AUTOSAR XML (schema 4-3-0)
package /Impl_SWC_HALIN_CDD_ARPkg
  swc implementation Impl_SWC_HALIN_CDD_type: programming-language=C, sw-version=1.0.0, vendor-id=0, behavior=SWC_HALIN_CDD_type_IB
    code-descriptors:
      code SRC: artifact-descriptors=autosar-engineering-object={short-label=EngObject, category=SWSRC}
    resource consumption ResourceConsumption
      memory section Mem_SWC_HALIN_CDD_CAL: size=0, sw-addrmethod=CAL, symbol=CAL
      memory section Mem_SWC_HALIN_CDD_CODE: size=0, sw-addrmethod=CODE, symbol=CODE
package /Impl_Type_HALIN_CDD_ARPkg
  13 x impl type:
    BHAL_APM_outputs: category=STRUCTURE
      58 x element, all with category=TYPE_REFERENCE:
        VHAL_PASDRMR_cm: implementation-data-type=uint8
        VHAL_PASDRML_cm: implementation-data-type=uint8
        VHAL_PASDRCR_cm: implementation-data-type=uint8
        VHAL_PASDRCL_cm: implementation-data-type=uint8
        VHAL_PASDFMR_cm: implementation-data-type=uint8
        VHAL_PASDFML_cm: implementation-data-type=uint8
        VHAL_PASDFCR_cm: implementation-data-type=uint8
        VHAL_PASDFCL_cm: implementation-data-type=uint8
        VHAL_APSDRLR_cm: implementation-data-type=uint16
        VHAL_APSDRLL_cm: implementation-data-type=uint16
        VHAL_APSDFLR_cm: implementation-data-type=uint16
        VHAL_APSDFLL_cm: implementation-data-type=uint16
        VHAL_PASAFCL_enum: implementation-data-type=uint8
        VHAL_PASARMR_enum: implementation-data-type=uint8
        VHAL_PASARML_enum: implementation-data-type=uint8
        VHAL_PASARCR_enum: implementation-data-type=uint8
        VHAL_PASARCL_enum: implementation-data-type=uint8
        VHAL_PASAFMR_enum: implementation-data-type=uint8
        VHAL_PASAFML_enum: implementation-data-type=uint8
        VHAL_PASAFCR_enum: implementation-data-type=uint8
        VHAL_USSStaRMR_flg: implementation-data-type=boolean
        VHAL_USSStaRML_flg: implementation-data-type=boolean
        VHAL_USSStaRLR_flg: implementation-data-type=boolean
        VHAL_USSStaRLL_flg: implementation-data-type=boolean
        VHAL_USSStaRCR_flg: implementation-data-type=boolean
        VHAL_USSStaRCL_flg: implementation-data-type=boolean
        VHAL_USSStaFMR_flg: implementation-data-type=boolean
        VHAL_USSStaFML_flg: implementation-data-type=boolean
        VHAL_USSStaFLR_flg: implementation-data-type=boolean
        VHAL_USSStaFLL_flg: implementation-data-type=boolean
        VHAL_USSStaFCR_flg: implementation-data-type=boolean
        VHAL_USSStaFCL_flg: implementation-data-type=boolean
        VHAL_Chime_enum: implementation-data-type=uint8
        VHAL_SNSRLayout_enum: implementation-data-type=uint8
        VHAL_StaFSya_flg: implementation-data-type=boolean
        VHAL_ModOperation_enum: implementation-data-type=uint8
        VHAL_APSProgressPCT_pct: implementation-data-type=float32
        VHAL_APSRQDisplay_enum: implementation-data-type=uint8
        VHAL_APSSWVer_enum: implementation-data-type=uint8
        VHAL_APSHWVer_enum: implementation-data-type=uint8
        VHAL_APSExitCondition_enum: implementation-data-type=uint8
        VHAL_APSAngleTarget_Deg: implementation-data-type=float32
        VHAL_APSStaSystem_enum: implementation-data-type=uint8
        VHAL_APSVRqEPASCtrl_flg: implementation-data-type=boolean
        VHAL_APSRqEPASCtrl_flg: implementation-data-type=boolean
        VHAL_APSReq_enum: implementation-data-type=uint8
        VHAL_APSDecReq_mps2: implementation-data-type=float32
        VHAL_APSDecReqA_flg: implementation-data-type=boolean
        VHAL_APSShiftPosnReq_enum: implementation-data-type=uint8
        VHAL_APSSpeedCMD_kph: implementation-data-type=float32
        VHAL_APSVMCReqA_flg: implementation-data-type=boolean
        VHAL_CAASSta_enum: implementation-data-type=uint8
        VHAL_CAASVMCReqA_flg: implementation-data-type=boolean
        VHAL_APSPwrReq_enum: implementation-data-type=uint8
        VHAL_RAPSBCMLockReq_flg: implementation-data-type=boolean
        VHAL_RAPSBCMLamp_enum: implementation-data-type=uint8
        VHAL_RAPSErrWarnSta_enum: implementation-data-type=uint8
        VHAL_RAPSErrLv1_flg: implementation-data-type=boolean
    BHAL_DDM_outputs: category=STRUCTURE
      element VHAL_ClearDTCcmd_flg: implementation-data-type=boolean
    BHAL_DID_outputs: category=STRUCTURE
      32 x element, all with category=TYPE_REFERENCE:
        VHAL_DIDStaXWDMode_raw: implementation-data-type=uint8
        VHAL_XWDMode_raw: implementation-data-type=uint8
        VHAL_DIDStaDKCKey_raw: implementation-data-type=uint8
        VHAL_DKCKey_raw: implementation-data-type=u8_Array8_type
        VHAL_DIDStaDynoMode_raw: implementation-data-type=uint8
        VHAL_DynoMode_raw: implementation-data-type=uint8
        VHAL_DIDStaTurnLampFRThreCurr_raw: implementation-data-type=uint8
        VHAL_TurnLampFRThreCurr_raw: implementation-data-type=uint8
        VHAL_DIDStaTurnLampRRThreCurr_raw: implementation-data-type=uint8
        VHAL_TurnLampRRThreCurr_raw: implementation-data-type=uint8
        VHAL_DIDStaTurnLampFLThreCurr_raw: implementation-data-type=uint8
        VHAL_TurnLampFLThreCurr_raw: implementation-data-type=uint8
        VHAL_DIDStaTurnLampRLThreCurr_raw: implementation-data-type=uint8
        VHAL_TurnLampRLThreCurr_raw: implementation-data-type=uint8
        VHAL_DIDStaFMHTimer_raw: implementation-data-type=uint8
        VHAL_FMHTimer_raw: implementation-data-type=uint8
        VHAL_DIDStaAutoLock_raw: implementation-data-type=uint8
        VHAL_AutoLock_raw: implementation-data-type=uint8
        VHAL_DIDStaDRLDis_raw: implementation-data-type=uint8
        VHAL_DRLDis_raw: implementation-data-type=uint8
        VHAL_DIDStaAutoWipHSpdEN_raw: implementation-data-type=uint8
        VHAL_AutoWipHSpdEN_raw: implementation-data-type=uint8
        VHAL_DIDStaWipRLSCmdHoldFilter_raw: implementation-data-type=uint8
        VHAL_WipRLSCmdHoldFilter_raw: implementation-data-type=uint8
        VHAL_DIDStaWipRLSCmdCutFilter_raw: implementation-data-type=uint8
        VHAL_WipRLSCmdCutFilter_raw: implementation-data-type=uint8
        VHAL_DIDStaUSSConfig_raw: implementation-data-type=uint8
        VHAL_USSConfig_raw: implementation-data-type=u8_Array16_type
        VHAL_DIDStaTireSize_raw: implementation-data-type=uint8
        VHAL_TireSize_raw: implementation-data-type=u8_Array16_type
        VHAL_DIDStaAPSFunConfig_raw: implementation-data-type=uint8
        VHAL_APSFunConfig_raw: implementation-data-type=u8_Array16_type
    BHAL_DKC_outputs: category=STRUCTURE
      21 x element, all with category=TYPE_REFERENCE:
        VHAL_DKCDecReVehData_enum: implementation-data-type=uint8
        VHAL_DKCDecRemotePW_enum: implementation-data-type=uint8
        VHAL_DKCDecPCommandToBCM_enum: implementation-data-type=uint8
        VHAL_DKCDecPCommandToPTG_enum: implementation-data-type=uint8
        VHAL_DKCDecPDKeyAreaLockUnlock_enum: implementation-data-type=uint8
        VHAL_DKCDecPDKeyAreaPS_enum: implementation-data-type=uint8
        VHAL_DKCDecPDKeyAreaPTG_enum: implementation-data-type=uint8
        VHAL_DKCDecPDKeyWelcome_enum: implementation-data-type=uint8
        VHAL_DKCDecPDkeyShowIVI_enum: implementation-data-type=uint8
        VHAL_DKCDecPKeyMiss_flg: implementation-data-type=boolean
        VHAL_DKCDecPKeyMode_enum: implementation-data-type=uint8
        VHAL_DKCDecPUIDLowPower_flg: implementation-data-type=boolean
        VHAL_TimeSNDKCFbk_cnt: implementation-data-type=uint32
        VHAL_DKCDecryptionFail_flg: implementation-data-type=boolean
        VHAL_NFCDoorSta_flg: implementation-data-type=boolean
        VHAL_NFCLidASta_flg: implementation-data-type=boolean
        VHAL_KeyFobAreaU16_enum: implementation-data-type=uint16
        VHAL_UIDButtonCmd_enum: implementation-data-type=uint8
        VHAL_BTConnectSta_enum: implementation-data-type=uint8
        VHAL_UIDBatVoltx1000_V: implementation-data-type=uint16
        VHAL_DKCBTRSSI_dB: implementation-data-type=sint8
    BHAL_GPIO_outputs: category=STRUCTURE
      25 x element, all with category=TYPE_REFERENCE:
        VHAL_AccelPedal1Vol_V: implementation-data-type=float32
        VHAL_AccelPedal2Vol_V: implementation-data-type=float32
        VHAL_CrashInputFreq_Hz: implementation-data-type=float32
        VHAL_CrashInputDuty_pct: implementation-data-type=float32
        VHAL_BrakeSWGPIO_flg: implementation-data-type=boolean
        VHAL_EmergencyExitSW_flg: implementation-data-type=boolean
        VHAL_TailgateSW_flg: implementation-data-type=boolean
        VHAL_LeftTurnSW_flg: implementation-data-type=boolean
        VHAL_RightTurnSW_flg: implementation-data-type=boolean
        VHAL_FrontDoorSW_flg: implementation-data-type=boolean
        VHAL_MidDoorSW_flg: implementation-data-type=boolean
        VHAL_OSDoorSwOpen_flg: implementation-data-type=boolean
        VHAL_OSDoorSwClose_flg: implementation-data-type=boolean
        VHAL_HazardSW_flg: implementation-data-type=boolean
        VHAL_BrakeLampSW_flg: implementation-data-type=boolean
        VHAL_TrunkHanSW_flg: implementation-data-type=boolean
        VHAL_SeatSW_flg: implementation-data-type=boolean
        VHAL_CrashSignalGPIO_flg: implementation-data-type=boolean
        VHAL_HWID{1..4}_enum: implementation-data-type=uint8
        VHAL_PushButton_flg: implementation-data-type=boolean
        VHAL_AlcoholPass_flg: implementation-data-type=boolean
        VHAL_BmsAplus_flg: implementation-data-type=boolean
    BHAL_IMU_outputs: category=STRUCTURE
      12 x element, all with category=TYPE_REFERENCE, implementation-data-type=sint16:
        VHAL_MemOffsetGyroX_raw16
        VHAL_MemOffsetGyroY_raw16
        VHAL_MemOffsetGyroZ_raw16
        VHAL_MemOffsetAccX_raw16
        VHAL_MemOffsetAccY_raw16
        VHAL_MemOffsetAccZ_raw16
        VHAL_SensingGyroX_raw16
        VHAL_SensingGyroY_raw16
        VHAL_SensingGyroZ_raw16
        VHAL_SensingAccX_raw16
        VHAL_SensingAccY_raw16
        VHAL_SensingAccZ_raw16
    BHAL_SYS_outputs: category=STRUCTURE
      349 x element, all with category=TYPE_REFERENCE:
        VHAL_CarMode1_cnt: implementation-data-type=uint8
        VHAL_CarModel2_cnt: implementation-data-type=uint8
        VHAL_CarModel3_cnt: implementation-data-type=uint8
        VHAL_ECU1_cnt: implementation-data-type=uint8
        VHAL_ECU2_cnt: implementation-data-type=uint8
        VHAL_Major1_cnt: implementation-data-type=uint8
        VHAL_Major2_cnt: implementation-data-type=uint8
        VHAL_Minor1_cnt: implementation-data-type=uint8
        VHAL_Minor2_cnt: implementation-data-type=uint8
        VHAL_Patch1_cnt: implementation-data-type=uint8
        VHAL_Patch2_cnt: implementation-data-type=uint8
        VHAL_Country1_cnt: implementation-data-type=uint8
        VHAL_Country2_cnt: implementation-data-type=uint8
        VHAL_Variation_cnt: implementation-data-type=uint8
        VHAL_ECUGen1_cnt: implementation-data-type=uint8
        VHAL_ECUGen2_cnt: implementation-data-type=uint8
        VHAL_DrivingMode_cnt: implementation-data-type=uint8
        VHAL_ModelYear_cnt: implementation-data-type=uint8
        VHAL_Var4_cnt: implementation-data-type=uint8
        VHAL_Var5_cnt: implementation-data-type=uint8
        VHAL_Dash1_cnt: implementation-data-type=uint8
        VHAL_Change1_cnt: implementation-data-type=uint8
        VHAL_Change2_cnt: implementation-data-type=uint8
        VHAL_Dash2_cnt: implementation-data-type=uint8
        VHAL_SHA{1..8}_cnt: implementation-data-type=uint8
        VHAL_AcoreReadyToSlp_flg: implementation-data-type=boolean
        VHAL_PwrReq_OTA_enum: implementation-data-type=uint8
        VHAL_AllowMovThd_OTA_enum: implementation-data-type=uint8
        VHAL_EvccAplusPwrUpReq_flg: implementation-data-type=boolean
        VHAL_DrivetrainSelect_enum: implementation-data-type=uint8
        VHAL_ReadFlashCorrect_flg: implementation-data-type=boolean
        VHAL_FlashAntitheft_enum: implementation-data-type=uint8
        VHAL_RandomnumberY_raw{1..8}: implementation-data-type=uint8
        VHAL_FlashACModeSet123_enum: implementation-data-type=uint8
        VHAL_FlashFace_enum: implementation-data-type=uint8
        VHAL_FlashFoot_enum: implementation-data-type=uint8
        VHAL_FlashFrost_enum: implementation-data-type=uint8
        VHAL_FlashFaceM_enum: implementation-data-type=uint8
        VHAL_FlashFootM_enum: implementation-data-type=uint8
        VHAL_FlashCCUSyncSts_enum: implementation-data-type=uint8
        VHAL_FlashACForceOFF_flg: implementation-data-type=boolean
        VHAL_FlashsigRecircSt_enum: implementation-data-type=uint8
        VHAL_FlashRecAutoFlg_enum: implementation-data-type=uint8
        VHAL_FlashAirIntenZone1M_enum: implementation-data-type=uint8
        VHAL_Flashfdefog_enum: implementation-data-type=uint8
        VHAL_FlashsigSetTempZon1St_C: implementation-data-type=uint8
        VHAL_FlashsigSetTempZon2StM_C: implementation-data-type=uint8
        VHAL_FlashCountAlarm_enum: implementation-data-type=uint8
        VHAL_FlashMFSWTri_flg: implementation-data-type=boolean
        VHAL_FlashMirrorFlodPos_flg: implementation-data-type=boolean
        VHAL_FlashFuelDoorPos_flg: implementation-data-type=boolean
        VHAL_FlashLockSetting_enum: implementation-data-type=uint8
        VHAL_FlashMFRDNBrightReq_pct: implementation-data-type=uint8
        VHAL_FlashRoomLampMode_enum: implementation-data-type=uint8
        VHAL_FlashWiperFixMode_flg: implementation-data-type=boolean
        VHAL_FlashIVIPTGUSStaSW_enum: implementation-data-type=uint8
        VHAL_AnyNMID_flg: implementation-data-type=boolean
        VHAL_CurrentNmState_enum: implementation-data-type=uint8
        VHAL_NvmProtectSta_flg: implementation-data-type=boolean
        VHAL_AuxBattVolmV_mV: implementation-data-type=uint16
        VHAL_Pedal1Ref5V_V: implementation-data-type=float32
        VHAL_Pedal2Ref5V_V: implementation-data-type=float32
        VHAL_EAPS1MINMem_pct: implementation-data-type=float32
        VHAL_EAPS2MINMem_pct: implementation-data-type=float32
        VHAL_FlashHoodSW_flg: implementation-data-type=boolean
        VHAL_FlashTailgateSW_flg: implementation-data-type=boolean
        VHAL_FlashCTDLockSW_flg: implementation-data-type=boolean
        VHAL_FlashTailgateHDSW_flg: implementation-data-type=boolean
        VHAL_NetworkReqCalled_flg: implementation-data-type=boolean
        VHAL_PmicBootReason_enum: implementation-data-type=uint8
        VHAL_WisrBootReason_raw32: implementation-data-type=uint32
        VHAL_FlashAPMDoorControlSta_flg: implementation-data-type=boolean
        VHAL_AcoreRebootCmd_flg: implementation-data-type=boolean
        VHAL_DIDGetDynoMode_flg: implementation-data-type=boolean
        VHAL_CAN{1..6}BusOff_flg: implementation-data-type=boolean
        VHAL_funAuto_flg: implementation-data-type=boolean
        VHAL_DiagDRLOFF_flg: implementation-data-type=boolean
        VHAL_DiagFMHT_s: implementation-data-type=float32
        VHAL_DiagFLTC_mA: implementation-data-type=float32
        VHAL_DiagFRTC_mA: implementation-data-type=float32
        VHAL_DiagRLTC_mA: implementation-data-type=float32
        VHAL_DiagRRTC_mA: implementation-data-type=float32
        VHAL_USSConfig_raw8: implementation-data-type=u8_Array16_type
        VHAL_TireSize_raw8: implementation-data-type=u8_Array16_type
        VHAL_APSFunConfig_raw8: implementation-data-type=u8_Array16_type
        VHAL_FlashfUnlockSingle_flg: implementation-data-type=boolean
        VHAL_FlashRegenMode_enum: implementation-data-type=uint8
        VHAL_FlashAmbFunEN_enum: implementation-data-type=uint8
        VHAL_FlashAmbWelEN_enum: implementation-data-type=uint8
        VHAL_FlashAmbDimEN_enum: implementation-data-type=uint8
        VHAL_FlashAmbLinkDriSta_enum: implementation-data-type=uint8
        VHAL_FlashAmbPwrWarnEN_enum: implementation-data-type=uint8
        VHAL_FlashAmbODAEN_enum: implementation-data-type=uint8
        VHAL_FlashAmbColorSta{1..5}_enum: implementation-data-type=uint8
        VHAL_FlashAmbColorSta7_enum: implementation-data-type=uint8
        VHAL_FlashAmbBrightnessSta{1..5}_enum: implementation-data-type=uint8
        VHAL_FlashAmbBrightnessSta7_enum: implementation-data-type=uint8
        VHAL_FlashTurnSwTSet123_enum: implementation-data-type=uint8
        VHAL_FlashTurnSwTSet457_enum: implementation-data-type=uint8
        VHAL_FlashAirIntZ3Sta_enum: implementation-data-type=uint8
        VHAL_FlashPsEVentModeSta_enum: implementation-data-type=uint8
        VHAL_FlashDrEVentModeSta_enum: implementation-data-type=uint8
        VHAL_FlashDrEVentZSta_enum: implementation-data-type=uint8
        VHAL_FlashCLEVentZSta_enum: implementation-data-type=uint8
        VHAL_FlashPsEVentZSta_enum: implementation-data-type=uint8
        VHAL_FlashCREVentZSta_enum: implementation-data-type=uint8
        VHAL_FlashDrVentEN_enum: implementation-data-type=uint8
        VHAL_FlashDrEVentYSta_enum: implementation-data-type=uint8
        VHAL_FlashCLVentEN_enum: implementation-data-type=uint8
        VHAL_FlashCLEVentYSta_enum: implementation-data-type=uint8
        VHAL_FlashPsVentEN_enum: implementation-data-type=uint8
        VHAL_FlashPsEVentYSta_enum: implementation-data-type=uint8
        VHAL_FlashCRVentEN_enum: implementation-data-type=uint8
        VHAL_FlashCREVentYSta_enum: implementation-data-type=uint8
        VHAL_FlashFGSAirIntSta_enum: implementation-data-type=uint8
        VHAL_FlashFGSChSta_enum: implementation-data-type=uint8
        VHAL_FlashFGSIONSWSta_enum: implementation-data-type=uint8
        VHAL_FlashWalkOutLkEN_enum: implementation-data-type=uint8
        VHAL_FlashWalkInUnLkEN_enum: implementation-data-type=uint8
        VHAL_FlashFollowMeENFun_enum: implementation-data-type=uint8
        VHAL_ResetPedalZeroPosReq_enum: implementation-data-type=uint8
        VHAL_FlashPTGUserHeight{1..5}_cnt: implementation-data-type=uint16
        VHAL_FlashPTGUserHeight7_cnt: implementation-data-type=uint16
        VHAL_FlashPTGOpenHeight12_enum: implementation-data-type=uint8
        VHAL_FlashPTGOpenHeight34_enum: implementation-data-type=uint8
        VHAL_FlashPTGOpenHeight57_enum: implementation-data-type=uint8
        VHAL_FlashACCLevelSta12_enum: implementation-data-type=uint8
        VHAL_FlashACCLevelSta34_enum: implementation-data-type=uint8
        VHAL_FlashACCLevelSta57_enum: implementation-data-type=uint8
        VHAL_AutoWipHSpdEN_flg: implementation-data-type=boolean
        VHAL_WipRLSCmdHoldEN_flg: implementation-data-type=boolean
        VHAL_WipRLSCmdHoldTime_s: implementation-data-type=uint8
        VHAL_WipRLSCmdCutEN_flg: implementation-data-type=boolean
        VHAL_WipRLSCmdCutTime_s: implementation-data-type=uint8
        VHAL_FlashAutoLock_enum: implementation-data-type=uint8
        VHAL_FlashAutoUnlock_enum: implementation-data-type=uint8
        VHAL_PmicBootPath_raw32: implementation-data-type=uint32
        VHAL_FlashTPMModelVersion_raw: implementation-data-type=uint8
        VHAL_FlashTPMModelVersionChkSum_raw: implementation-data-type=uint8
        VHAL_FlashMILDIST_km: implementation-data-type=float32
        VHAL_FlashWARMUPS_cnt: implementation-data-type=uint8
        VHAL_FlashCLRDIST_km: implementation-data-type=float32
        VHAL_FlashMILTIME_min: implementation-data-type=uint16
        VHAL_FlashCLRTIME_min: implementation-data-type=uint16
        VHAL_FlashNUMPSATRIPSFLTMEMCLR_cnt: implementation-data-type=uint16
        VHAL_FlashODOMETER_km: implementation-data-type=float32
        VHAL_FlashPSAR_sec: implementation-data-type=uint32
        VHAL_FlashPSAL_sec: implementation-data-type=uint32
        VHAL_FlashIPSAR_sec: implementation-data-type=uint32
        VHAL_FlashIPSAL_sec: implementation-data-type=uint32
        VHAL_FlashCPSAR_sec: implementation-data-type=uint32
        VHAL_FlashCPSAL_sec: implementation-data-type=uint32
        VHAL_FlashHVBNAH_Ahr: implementation-data-type=float32
        VHAL_FlashHVBNE_kWh: implementation-data-type=float32
        VHAL_FlashIGNCNTR_cnt: implementation-data-type=uint16
        VHAL_FlashTNBCPSAR_Ahr: implementation-data-type=float32
        VHAL_FlashTNBCPSAL_Ahr: implementation-data-type=float32
        VHAL_FlashTNECPSAR_kWh: implementation-data-type=float32
        VHAL_FlashTNECPSAL_kWh: implementation-data-type=float32
        VHAL_FlashTEBPSAR_kWh: implementation-data-type=float32
        VHAL_FlashTEBPSAL_kWh: implementation-data-type=float32
        VHAL_FlashTGEOVCR_kWh: implementation-data-type=float32
        VHAL_FlashTGEOVCL_kWh: implementation-data-type=float32
        VHAL_FlashGECHGOVCDCR_kWh: implementation-data-type=float32
        VHAL_FlashGECHGOVCDCL_kWh: implementation-data-type=float32
        VHAL_FlashGECHGOVCACR_kWh: implementation-data-type=float32
        VHAL_FlashGECHGOVCACL_kWh: implementation-data-type=float32
        VHAL_FlashRESSV2XENNONPSAR_kWh: implementation-data-type=float32
        VHAL_FlashRESSV2XENNONPSAL_kWh: implementation-data-type=float32
        VHAL_FlashPKERNumerator_kphsqr: implementation-data-type=uint32
        VHAL_FlashPKELNumerator_kphsqr: implementation-data-type=uint32
        VHAL_FlashResetCDEODTR_km: implementation-data-type=float32
        VHAL_FlashAvgBattTempPSAR_C: implementation-data-type=float32
        VHAL_FlashAvgBattTempPSAL_C: implementation-data-type=float32
        VHAL_FlashAvgBattTempOVCR_C: implementation-data-type=float32
        VHAL_FlashAvgBattTempOVCL_C: implementation-data-type=float32
        VHAL_FlashAvgBattTempOFFR_C: implementation-data-type=float32
        VHAL_FlashAvgBattTempOFFL_C: implementation-data-type=float32
        VHAL_FlashQTYPSATRIPSR_cnt: implementation-data-type=uint32
        VHAL_FlashQTYPSATRIPSL_cnt: implementation-data-type=uint32
        VHAL_FlashRESSCNTDODRNGR_cnt: implementation-data-type=u16_Array8_type
        VHAL_FlashRESSCNTDODRNGL_cnt: implementation-data-type=u16_Array8_type
        VHAL_FlashETMATOER_kWh: implementation-data-type=float32
        VHAL_FlashETMATOEL_kWh: implementation-data-type=float32
        VHAL_FlashETMBTOER_kWh: implementation-data-type=float32
        VHAL_FlashETMBTOEL_kWh: implementation-data-type=float32
        VHAL_FlashRESSTIMESOCPSARNGR_s: implementation-data-type=u32_Array8_type
        VHAL_FlashRESSTIMESOCPSARNGL_s: implementation-data-type=u32_Array8_type
        VHAL_FlashRESSTIMESOCCHGRNGR_s: implementation-data-type=u32_Array8_type
        VHAL_FlashRESSTIMESOCCHGRNGL_s: implementation-data-type=u32_Array8_type
        VHAL_FlashRESSTIMESOCOFFRNGR_s: implementation-data-type=u32_Array8_type
        VHAL_FlashRESSTIMESOCOFFRNGL_s: implementation-data-type=u32_Array8_type
        VHAL_FlashMAXBATTEMPL_C: implementation-data-type=float32
        VHAL_FlashMINBATTEMPL_C: implementation-data-type=float32
        VHAL_FlashAVGBATTEMPL_sec: implementation-data-type=uint32
        VHAL_FlashAVGBATTEMPL_C: implementation-data-type=float32
        VHAL_FlashBattTempPSAR_sec: implementation-data-type=uint32
        VHAL_FlashBattTempPSAL_sec: implementation-data-type=uint32
        VHAL_FlashOVCR_sec: implementation-data-type=uint32
        VHAL_FlashOVCL_sec: implementation-data-type=uint32
        VHAL_FlashOFFR_sec: implementation-data-type=uint32
        VHAL_FlashOFFL_sec: implementation-data-type=uint32
        VHAL_VinCode_cnt: implementation-data-type=u8_Array17_type
        VHAL_FlashChkLFID_raw: implementation-data-type=uint32
        VHAL_FlashChkRFID_raw: implementation-data-type=uint32
        VHAL_FlashChkLRID_raw: implementation-data-type=uint32
        VHAL_FlashChkRRID_raw: implementation-data-type=uint32
        VHAL_FlashLFID_raw: implementation-data-type=uint32
        VHAL_FlashRFID_raw: implementation-data-type=uint32
        VHAL_FlashLRID_raw: implementation-data-type=uint32
        VHAL_FlashRRID_raw: implementation-data-type=uint32
        VHAL_Flashchkdatavalid_enum: implementation-data-type=uint8
        VHAL_Flashdatavalid_enum: implementation-data-type=uint8
        VHAL_LFSensorFail_flg: implementation-data-type=boolean
        VHAL_RFSensorFail_flg: implementation-data-type=boolean
        VHAL_LRSensorFail_flg: implementation-data-type=boolean
        VHAL_RRSensorFail_flg: implementation-data-type=boolean
        VHAL_LFWheelPSW_raw8: implementation-data-type=uint8
        VHAL_RFWheelPSW_raw8: implementation-data-type=uint8
        VHAL_LRWheelPSW_raw8: implementation-data-type=uint8
        VHAL_RRWheelPSW_raw8: implementation-data-type=uint8
        VHAL_LFPindi_enum: implementation-data-type=uint8
        VHAL_RFPindi_enum: implementation-data-type=uint8
        VHAL_LRPindi_enum: implementation-data-type=uint8
        VHAL_RRPindi_enum: implementation-data-type=uint8
        VHAL_LFP20_raw8: implementation-data-type=uint8
        VHAL_RFP20_raw8: implementation-data-type=uint8
        VHAL_LRP20_raw8: implementation-data-type=uint8
        VHAL_RRP20_raw8: implementation-data-type=uint8
        VHAL_LFWheelPress_raw8: implementation-data-type=uint8
        VHAL_RFWheelPress_raw8: implementation-data-type=uint8
        VHAL_LRWheelPress_raw8: implementation-data-type=uint8
        VHAL_RRWheelPress_raw8: implementation-data-type=uint8
        VHAL_LFWheelTemp_C: implementation-data-type=uint8
        VHAL_RFWheelTemp_C: implementation-data-type=uint8
        VHAL_LRWheelTemp_C: implementation-data-type=uint8
        VHAL_RRWheelTemp_C: implementation-data-type=uint8
        VHAL_unlearnSfali_flg: implementation-data-type=boolean
        VHAL_unlearnSfailvalid_enum: implementation-data-type=uint8
        VHAL_Prepresstempvalid_enum: implementation-data-type=uint8
        VHAL_FlashS{1..4}ID_raw: implementation-data-type=uint32
        VHAL_FlashIDvalid_enum: implementation-data-type=uint8
        VHAL_TPMSSensorIDRegSta_raw: implementation-data-type=uint8
        VHAL_FlashHMIKey{1..8}Func_enum: implementation-data-type=uint8
        VHAL_FlashAutoWipHSpdEN_flg: implementation-data-type=boolean
        VHAL_FlashDIDModelVersion_raw: implementation-data-type=uint8
        VHAL_FlashDIDModelVersionChkSum_raw: implementation-data-type=uint8
        VHAL_FlashAirIntenZone1MSet{2..5}_enum: implementation-data-type=uint8
        VHAL_FlashAirIntenZone1MSet7_enum: implementation-data-type=uint8
        VHAL_FlashAirIntenZone3MSet{2..5}_enum: implementation-data-type=uint8
        VHAL_FlashAirIntenZone3MSet7_enum: implementation-data-type=uint8
        VHAL_FlashFGSChStaSet457_enum: implementation-data-type=uint8
        VHAL_FlashFGSAirIntStaSet457_enum: implementation-data-type=uint8
        VHAL_FlashDrEVentModeStaSet457_enum: implementation-data-type=uint8
        VHAL_FlashPsEVentModeStaSet457_enum: implementation-data-type=uint8
        VHAL_FlashDrEVentZStaSet{2..5}_enum: implementation-data-type=uint8
        VHAL_FlashDrEVentZStaSet7_enum: implementation-data-type=uint8
        VHAL_FlashCLEVentZStaSet{2..5}_enum: implementation-data-type=uint8
        VHAL_FlashCLEVentZStaSet7_enum: implementation-data-type=uint8
        VHAL_FlashPsEVentZStaSet{2..5}_enum: implementation-data-type=uint8
        VHAL_FlashPsEVentZStaSet7_enum: implementation-data-type=uint8
        VHAL_FlashCREVentZStaSet{2..5}_enum: implementation-data-type=uint8
        VHAL_FlashCREVentZStaSet7_enum: implementation-data-type=uint8
        VHAL_FlashDrEVentYStaSet{2..5}_enum: implementation-data-type=uint8
        VHAL_FlashDrEVentYStaSet7_enum: implementation-data-type=uint8
        VHAL_FlashCLEVentYStaSet{2..5}_enum: implementation-data-type=uint8
        VHAL_FlashCLEVentYStaSet7_enum: implementation-data-type=uint8
        VHAL_FlashPsEVentYStaSet{2..5}_enum: implementation-data-type=uint8
        VHAL_FlashPsEVentYStaSet7_enum: implementation-data-type=uint8
        VHAL_FlashCREVentYStaSet{2..5}_enum: implementation-data-type=uint8
        VHAL_FlashCREVentYStaSet7_enum: implementation-data-type=uint8
        VHAL_FlashACModeSet457_enum: implementation-data-type=uint8
        VHAL_FlashSettempZon1Set{2..5}_enum: implementation-data-type=uint8
        VHAL_FlashSettempZon1Set7_enum: implementation-data-type=uint8
        VHAL_FlashJugKeepUnLZone_flg: implementation-data-type=boolean
    BHAL_TPMS_outputs: category=STRUCTURE
      52 x element, all with category=TYPE_REFERENCE:
        VHAL_TPMSDataIn_flg: implementation-data-type=boolean
        VHAL_TPMSID_raw: implementation-data-type=uint32
        VHAL_TPMSPressure_raw: implementation-data-type=uint8
        VHAL_TPMSTemp_raw: implementation-data-type=uint8
        VHAL_TPMSSta_enum: implementation-data-type=uint8
        VHAL_TPMSPressureMi_raw: implementation-data-type=uint8
        VHAL_TPMSCRC_crc: implementation-data-type=uint8
        VHAL_TPMSCRCCalc_crc: implementation-data-type=uint8
        VHAL_TPMSFAT_flg: implementation-data-type=boolean
        VHAL_TPMSBattLow_flg: implementation-data-type=boolean
        VHAL_TPMSStorge_flg: implementation-data-type=boolean
        VHAL_LFID_raw: implementation-data-type=uint32
        VHAL_RFID_raw: implementation-data-type=uint32
        VHAL_LRID_raw: implementation-data-type=uint32
        VHAL_RRID_raw: implementation-data-type=uint32
        VHAL_ChkStorge_flg: implementation-data-type=boolean
        VHAL_ChkLFID_raw: implementation-data-type=uint32
        VHAL_ChkRFID_raw: implementation-data-type=uint32
        VHAL_ChkLRID_raw: implementation-data-type=uint32
        VHAL_ChkRRID_raw: implementation-data-type=uint32
        VHAL_FlashLFSensorFail_flg: implementation-data-type=boolean
        VHAL_FlashRFSensorFail_flg: implementation-data-type=boolean
        VHAL_FlashLRSensorFail_flg: implementation-data-type=boolean
        VHAL_FlashRRSensorFail_flg: implementation-data-type=boolean
        VHAL_FlashLFWheelPSW_raw8: implementation-data-type=uint8
        VHAL_FlashRFWheelPSW_raw8: implementation-data-type=uint8
        VHAL_FlashLRWheelPSW_raw8: implementation-data-type=uint8
        VHAL_FlashRRWheelPSW_raw8: implementation-data-type=uint8
        VHAL_FlashLFPindi_enum: implementation-data-type=uint8
        VHAL_FlashRFPindi_enum: implementation-data-type=uint8
        VHAL_FlashLRPindi_enum: implementation-data-type=uint8
        VHAL_FlashRRPindi_enum: implementation-data-type=uint8
        VHAL_FlashLFP20_raw8: implementation-data-type=uint8
        VHAL_FlashRFP20_raw8: implementation-data-type=uint8
        VHAL_FlashLRP20_raw8: implementation-data-type=uint8
        VHAL_FlashRRP20_raw8: implementation-data-type=uint8
        VHAL_FlashLFWheelPress_raw8: implementation-data-type=uint8
        VHAL_FlashRFWheelPress_raw8: implementation-data-type=uint8
        VHAL_FlashLRWheelPress_raw8: implementation-data-type=uint8
        VHAL_FlashRRWheelPress_raw8: implementation-data-type=uint8
        VHAL_FlashLFWheelTemp_C: implementation-data-type=uint8
        VHAL_FlashRFWheelTemp_C: implementation-data-type=uint8
        VHAL_FlashLRWheelTemp_C: implementation-data-type=uint8
        VHAL_FlashRRWheelTemp_C: implementation-data-type=uint8
        VHAL_FlashunlearnSfali_flg: implementation-data-type=boolean
        VHAL_S{1..4}ID_raw: implementation-data-type=uint32
        VHAL_Prepresstemptrust_flg: implementation-data-type=boolean
        VHAL_TPMSSensorIDRegSta_enum: implementation-data-type=uint8
        VHAL_TPMSTrigger_flg: implementation-data-type=boolean
    u8_Array16_type: category=ARRAY
      element u8_Array16: category=VALUE, array-size=16, array-size-semantics=FIXED-SIZE, base-type=uint8
    u8_Array8_type: category=ARRAY
      element u8_Array8: category=VALUE, array-size=8, array-size-semantics=FIXED-SIZE, base-type=uint8
    u16_Array8_type: category=ARRAY
      element u16_Array8: category=VALUE, array-size=8, array-size-semantics=FIXED-SIZE, base-type=uint16
    u32_Array8_type: category=ARRAY
      element u32_Array8: category=VALUE, array-size=8, array-size-semantics=FIXED-SIZE, base-type=uint32
    u8_Array17_type: category=ARRAY
      element u8_Array17: category=VALUE, array-size=17, array-size-semantics=FIXED-SIZE, base-type=uint8
package /Interface_HALIN_CDD_ARPkg
  8 x sender receiver interface:
    IF_BHAL_APM_outputs
      data BHAL_APM_outputs: type=BHAL_APM_outputs
    IF_BHAL_DDM_outputs
      data BHAL_DDM_outputs: type=BHAL_DDM_outputs
    IF_BHAL_DID_outputs
      data BHAL_DID_outputs: type=BHAL_DID_outputs
    IF_BHAL_DKC_outputs
      data BHAL_DKC_outputs: type=BHAL_DKC_outputs
    IF_BHAL_GPIO_outputs
      data BHAL_GPIO_outputs: type=BHAL_GPIO_outputs
    IF_BHAL_IMU_outputs
      data BHAL_IMU_outputs: type=BHAL_IMU_outputs
    IF_BHAL_SYS_outputs
      data BHAL_SYS_outputs: type=BHAL_SYS_outputs
    IF_BHAL_TPMS_outputs
      data BHAL_TPMS_outputs: type=BHAL_TPMS_outputs
package /SWC_HALIN_CDD_ARPkg
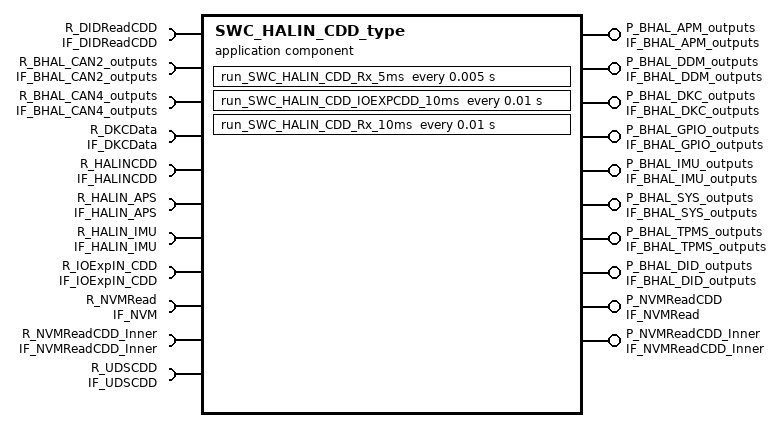
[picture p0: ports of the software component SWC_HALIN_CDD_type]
  application sw component type SWC_HALIN_CDD_type
    10 x provide port:
      P_BHAL_APM_outputs: provided-interface=IF_BHAL_APM_outputs
      P_BHAL_DDM_outputs: provided-interface=IF_BHAL_DDM_outputs
      P_BHAL_DKC_outputs: provided-interface=IF_BHAL_DKC_outputs
      P_BHAL_GPIO_outputs: provided-interface=IF_BHAL_GPIO_outputs
      P_BHAL_IMU_outputs: provided-interface=IF_BHAL_IMU_outputs
      P_BHAL_SYS_outputs: provided-interface=IF_BHAL_SYS_outputs
      P_BHAL_TPMS_outputs: provided-interface=IF_BHAL_TPMS_outputs
      P_BHAL_DID_outputs: provided-interface=IF_BHAL_DID_outputs
      P_NVMReadCDD: provided-interface=IF_NVMRead
      P_NVMReadCDD_Inner: provided-interface=IF_NVMReadCDD_Inner
    11 x require port:
      R_DIDReadCDD: required-interface=IF_DIDReadCDD
      R_BHAL_CAN2_outputs: required-interface=IF_BHAL_CAN2_outputs
      R_BHAL_CAN4_outputs: required-interface=IF_BHAL_CAN4_outputs
      R_DKCData: required-interface=IF_DKCData
      R_HALINCDD: required-interface=IF_HALINCDD
      R_HALIN_APS: required-interface=IF_HALIN_APS
      R_HALIN_IMU: required-interface=IF_HALIN_IMU
      R_IOExpIN_CDD: required-interface=IF_IOExpIN_CDD
      R_NVMRead: nv-require-com-spec{init-value=1024 x 0, variable=NV_FVTDataArray}, required-interface=IF_NVM
      R_NVMReadCDD_Inner: required-interface=IF_NVMReadCDD_Inner
      R_UDSCDD: required-interface=IF_UDSCDD
    behavior SWC_HALIN_CDD_type_IB: data-type-mapping=AppModeTypeMap, handle-termination-and-restart=NO-SUPPORT, port-api-option{enable-take-address=false, indirect-api=false, port=P_NVMReadCDD_Inner}
      timing event TE_HALIN_CDD_5ms: start-on-event=run_SWC_HALIN_CDD_Rx_5ms, period=0.005
      timing event TE_IOEXPCDD_10ms: start-on-event=run_SWC_HALIN_CDD_IOEXPCDD_10ms, period=0.01
      timing event TE_HALIN_10ms: start-on-event=run_SWC_HALIN_CDD_Rx_10ms, period=0.01
      operation invoked event oie_P_NVMReadCDD_Inner_NVM_ReadOperation: start-on-event=run_SWC_HALIN_CDD_NvmRead, operation=P_NVMReadCDD_Inner.NVM_ReadOperation
      explicit-inter-runnable-variables:
        16 x data:
          IRV_u16Array4_ApsInDist: type=u16_APSArray4_type
          IRV_u8Array12_ApsInUssSta: type=u8_USSArray12_type
          IRV_u8Array1024_NvmReadArray: type=u8_FVTNVMArray1024_type
          IRV_u8Array8_ApsInLevel: type=u8_APSLevelArray8_type
          IRV_u8Array8_PasInDist: type=u8_PASArray8_type
          IRV_u8Array9_TPMSData: type=u8_TPMSDataArray9_type
          IRV_u8_ApsInPASChime: type=uint8
          IRV_u8_ApsInSensorLayout: type=uint8
          IRV_u8_ApsInSysFailSta: type=uint8
          IRV_u8_ApsInSysMode: type=uint8
          IRV_u8_CTDSW: type=uint8
          IRV_u8_TPMSDataInSta: type=boolean
          IRV_u8_TrunkHanSW: type=uint8
          IRV_u8_PushButton: type=uint8
          IRV_u8_AlcoholPass: type=uint8
          IRV_u8_BMSAplus: type=uint8
      4 x runnable:
        run_SWC_HALIN_CDD_Rx_5ms
          data-receive-point-by-arguments:
            access drparg_BHAL_CAN2_outputs: accessed-variable=R_BHAL_CAN2_outputs.BHAL_CAN2_outputs
            access drparg_BHAL_CAN4_outputs: accessed-variable=R_BHAL_CAN4_outputs.BHAL_CAN4_outputs
            access drparg_u8Array8_DKCData: accessed-variable=R_DKCData.u8Array8_DKCData
          data-send-points:
            8 x access:
              dsp_BHAL_APM_outputs: accessed-variable=P_BHAL_APM_outputs.BHAL_APM_outputs
              dsp_BHAL_DDM_outputs: accessed-variable=P_BHAL_DDM_outputs.BHAL_DDM_outputs
              dsp_BHAL_DKC_outputs: accessed-variable=P_BHAL_DKC_outputs.BHAL_DKC_outputs
              dsp_BHAL_GPIO_outputs: accessed-variable=P_BHAL_GPIO_outputs.BHAL_GPIO_outputs
              dsp_BHAL_IMU_outputs: accessed-variable=P_BHAL_IMU_outputs.BHAL_IMU_outputs
              dsp_BHAL_SYS_outputs: accessed-variable=P_BHAL_SYS_outputs.BHAL_SYS_outputs
              dsp_BHAL_TPMS_outputs: accessed-variable=P_BHAL_TPMS_outputs.BHAL_TPMS_outputs
              dsp_BHAL_DID_outputs: accessed-variable=P_BHAL_DID_outputs.BHAL_DID_outputs
          read-local-variables:
            16 x access:
              IRV_u16Array4_ApsInDist: accessed-variable=IRV_u16Array4_ApsInDist
              IRV_u8Array12_ApsInUssSta: accessed-variable=IRV_u8Array12_ApsInUssSta
              IRV_u8Array1024_NvmReadArray: accessed-variable=IRV_u8Array1024_NvmReadArray
              IRV_u8Array8_ApsInLevel: accessed-variable=IRV_u8Array8_ApsInLevel
              IRV_u8Array8_PasInDist: accessed-variable=IRV_u8Array8_PasInDist
              IRV_u8Array9_TPMSData: accessed-variable=IRV_u8Array9_TPMSData
              IRV_u8_ApsInPASChime: accessed-variable=IRV_u8_ApsInPASChime
              IRV_u8_ApsInSensorLayout: accessed-variable=IRV_u8_ApsInSensorLayout
              IRV_u8_ApsInSysFailSta: accessed-variable=IRV_u8_ApsInSysFailSta
              IRV_u8_ApsInSysMode: accessed-variable=IRV_u8_ApsInSysMode
              IRV_u8_CTDSW: accessed-variable=IRV_u8_CTDSW
              IRV_u8_TPMSDataInSta: accessed-variable=IRV_u8_TPMSDataInSta
              IRV_u8_TrunkHanSW: accessed-variable=IRV_u8_TrunkHanSW
              IRV_u8_PushButton: accessed-variable=IRV_u8_PushButton
              IRV_u8_AlcoholPass: accessed-variable=IRV_u8_AlcoholPass
              IRV_u8_BMSAplus: accessed-variable=IRV_u8_BMSAplus
          47 x sync call, all with timeout=0.0:
            scp_CSOP_AnyNmID: operation=R_HALINCDD.CSOP_AnyNmID
            scp_CSOP_ApsGetData: operation=R_HALIN_APS.CSOP_ApsGetData
            scp_CSOP_CAN{1..6}BusOff: operation=R_HALINCDD.CSOP_CAN{1..6}BusOff
            scp_CSOP_DKCDecrypt: operation=R_HALINCDD.CSOP_DKCDecrypt
            scp_CSOP_DdmClearDTCNotifica: operation=R_UDSCDD.CSOP_DdmClearDTCNotification
            scp_CSOP_GetACoreReadyToSleep: operation=R_HALINCDD.CSOP_GetAcoreReadyToSleep
            scp_CSOP_GetAcoreRebootCmd: operation=R_HALINCDD.CSOP_GetAcoreRebootCmd
            scp_CSOP_GetAuxBattVoltage: operation=R_HALINCDD.CSOP_GetAuxBattVoltage
            scp_CSOP_GetBootReason: operation=R_HALINCDD.CSOP_GetBootReason
            scp_CSOP_GetBootPath: operation=R_HALINCDD.CSOP_GetBootPath
            scp_CSOP_GetEvccAplusPwrUpReq: operation=R_HALINCDD.CSOP_GetEvccAplusPwrUpReq
            scp_CSOP_GetHWID: operation=R_HALINCDD.u8Array4_HWID
            scp_CSOP_GetNmState: operation=R_HALINCDD.CSOP_GetNmState
            scp_CSOP_GetNvmProtectState: operation=R_HALINCDD.CSOP_GetNvmProtectState
            scp_CSOP_GetSWID: operation=R_HALINCDD.CSOP_GetSWID
            scp_CSOP_GetVinpAllowMoveThd: operation=R_HALINCDD.CSOP_GetVinpAllowMoveThdOta
            scp_CSOP_GetVinpPwrReqOta: operation=R_HALINCDD.CSOP_GetVinpPwrReqOta
            scp_CSOP_GetWISR: operation=R_HALINCDD.CSOP_GetWISR
            scp_CSOP_HALINCDD_DIRECT: operation=R_HALINCDD.CSOP_HALINCDD_DIRECT
            scp_CSOP_IMUGetOffsetVal: operation=R_HALIN_IMU.CSOP_IMUGetOffsetVal
            scp_CSOP_IMUGetSixAxisVal: operation=R_HALIN_IMU.CSOP_IMUGetSixAxisVal
            scp_CSOP_TPMSSensorIDRegGetSta: operation=R_HALINCDD.CSOP_TPMSSensorIDRegGetSta
            scp_CSOP_ReadPedalZeroPosReq: operation=R_HALINCDD.CSOP_ReadPedalZeroPosReq
            scp_CSOP_ResetPedalZeroPosReq: operation=R_HALINCDD.CSOP_ResetPedalZeroPosReq
            scp_CSOP_GetVinCode: operation=R_HALINCDD.CSOP_GetVinCode
            scp_CSOP_DIDGet_XWDMode: operation=R_DIDReadCDD.CSOP_DIDGet_XWDMode
            scp_CSOP_DIDGet_DKCKey: operation=R_DIDReadCDD.CSOP_DIDGet_DKCKey
            scp_CSOP_DIDGet_DynoMode: operation=R_DIDReadCDD.CSOP_DIDGet_DynoMode
            scp_CSOP_DIDGet_TurnLampFRThreCurr: operation=R_DIDReadCDD.CSOP_DIDGet_TurnLampFRThreCurr
            scp_CSOP_DIDGet_TurnLampRRThreCurr: operation=R_DIDReadCDD.CSOP_DIDGet_TurnLampRRThreCurr
            scp_CSOP_DIDGet_TurnLampFLThreCurr: operation=R_DIDReadCDD.CSOP_DIDGet_TurnLampFLThreCurr
            scp_CSOP_DIDGet_TurnLampRLThreCurr: operation=R_DIDReadCDD.CSOP_DIDGet_TurnLampRLThreCurr
            scp_CSOP_DIDGet_FMHTimer: operation=R_DIDReadCDD.CSOP_DIDGet_FMHTimer
            scp_CSOP_DIDGet_AutoLock: operation=R_DIDReadCDD.CSOP_DIDGet_AutoLock
            scp_CSOP_DIDGet_DRLDis: operation=R_DIDReadCDD.CSOP_DIDGet_DRLDis
            scp_CSOP_DIDGet_AutoWipHSpdEN: operation=R_DIDReadCDD.CSOP_DIDGet_AutoWipHSpdEN
            scp_CSOP_DIDGet_WipRLSCmdHoldFilter: operation=R_DIDReadCDD.CSOP_DIDGet_WipRLSCmdHoldFilter
            scp_CSOP_DIDGet_WipRLSCmdCutFilter: operation=R_DIDReadCDD.CSOP_DIDGet_WipRLSCmdCutFilter
            scp_CSOP_DIDGet_USSConfig: operation=R_DIDReadCDD.CSOP_DIDGet_USSConfig
            scp_CSOP_DIDGet_TireSize: operation=R_DIDReadCDD.CSOP_DIDGet_TireSize
            scp_CSOP_DIDGet_APSFunConfig: operation=R_DIDReadCDD.CSOP_DIDGet_APSFunConfig
            scp_NVM_ReadOperation: operation=R_NVMReadCDD_Inner.NVM_ReadOperation
        run_SWC_HALIN_CDD_NvmRead
          data-receive-point-by-arguments:
            access drparg_NV_FVTDataArray: accessed-variable=R_NVMRead.NV_FVTDataArray
          data-send-points:
            access dsp_u8_FVTNVMArray1024_type: accessed-variable=P_NVMReadCDD.u8Array1024_NVMReadData
          written-local-variables:
            access IRV_u8Array1024_NvmReadArray: accessed-variable=IRV_u8Array1024_NvmReadArray
        run_SWC_HALIN_CDD_IOEXPCDD_10ms
          sync call scp_CSOP_IOExpGetVal: operation=R_IOExpIN_CDD.CSOP_IOExpGetVal, timeout=0.0
          written-local-variables:
            5 x access:
              IRV_u8_CTDSW: accessed-variable=IRV_u8_CTDSW
              IRV_u8_TrunkHanSW: accessed-variable=IRV_u8_TrunkHanSW
              IRV_u8_PushButton: accessed-variable=IRV_u8_PushButton
              IRV_u8_AlcoholPass: accessed-variable=IRV_u8_AlcoholPass
              IRV_u8_BMSAplus: accessed-variable=IRV_u8_BMSAplus
        run_SWC_HALIN_CDD_Rx_10ms
          5 x sync call, all with timeout=0.0:
            scp_CSOP_ApsGetDist: operation=R_HALIN_APS.CSOP_ApsGetDist
            scp_CSOP_ApsGetDistLevel: operation=R_HALIN_APS.CSOP_ApsGetDistLevel
            scp_CSOP_ApsGetUssSta: operation=R_HALIN_APS.CSOP_ApsGetUssSta
            scp_CSOP_GetAPSOtherStatus: operation=R_HALIN_APS.CSOP_ApsGetOtherStatus
            scp_CSOP_TPMS_GetRawData: operation=R_HALINCDD.CSOP_TPMS_GetRawData
          written-local-variables:
            10 x access:
              IRV_u16Array4_ApsInDist: accessed-variable=IRV_u16Array4_ApsInDist
              IRV_u8Array12_ApsInUssSta: accessed-variable=IRV_u8Array12_ApsInUssSta
              IRV_u8Array8_ApsInLevel: accessed-variable=IRV_u8Array8_ApsInLevel
              IRV_u8Array8_PasInDist: accessed-variable=IRV_u8Array8_PasInDist
              IRV_u8Array9_TPMSData: accessed-variable=IRV_u8Array9_TPMSData
              IRV_u8_ApsInPASChime: accessed-variable=IRV_u8_ApsInPASChime
              IRV_u8_ApsInSensorLayout: accessed-variable=IRV_u8_ApsInSensorLayout
              IRV_u8_ApsInSysFailSta: accessed-variable=IRV_u8_ApsInSysFailSta
              IRV_u8_ApsInSysMode: accessed-variable=IRV_u8_ApsInSysMode
              IRV_u8_TPMSDataInSta: accessed-variable=IRV_u8_TPMSDataInSta
